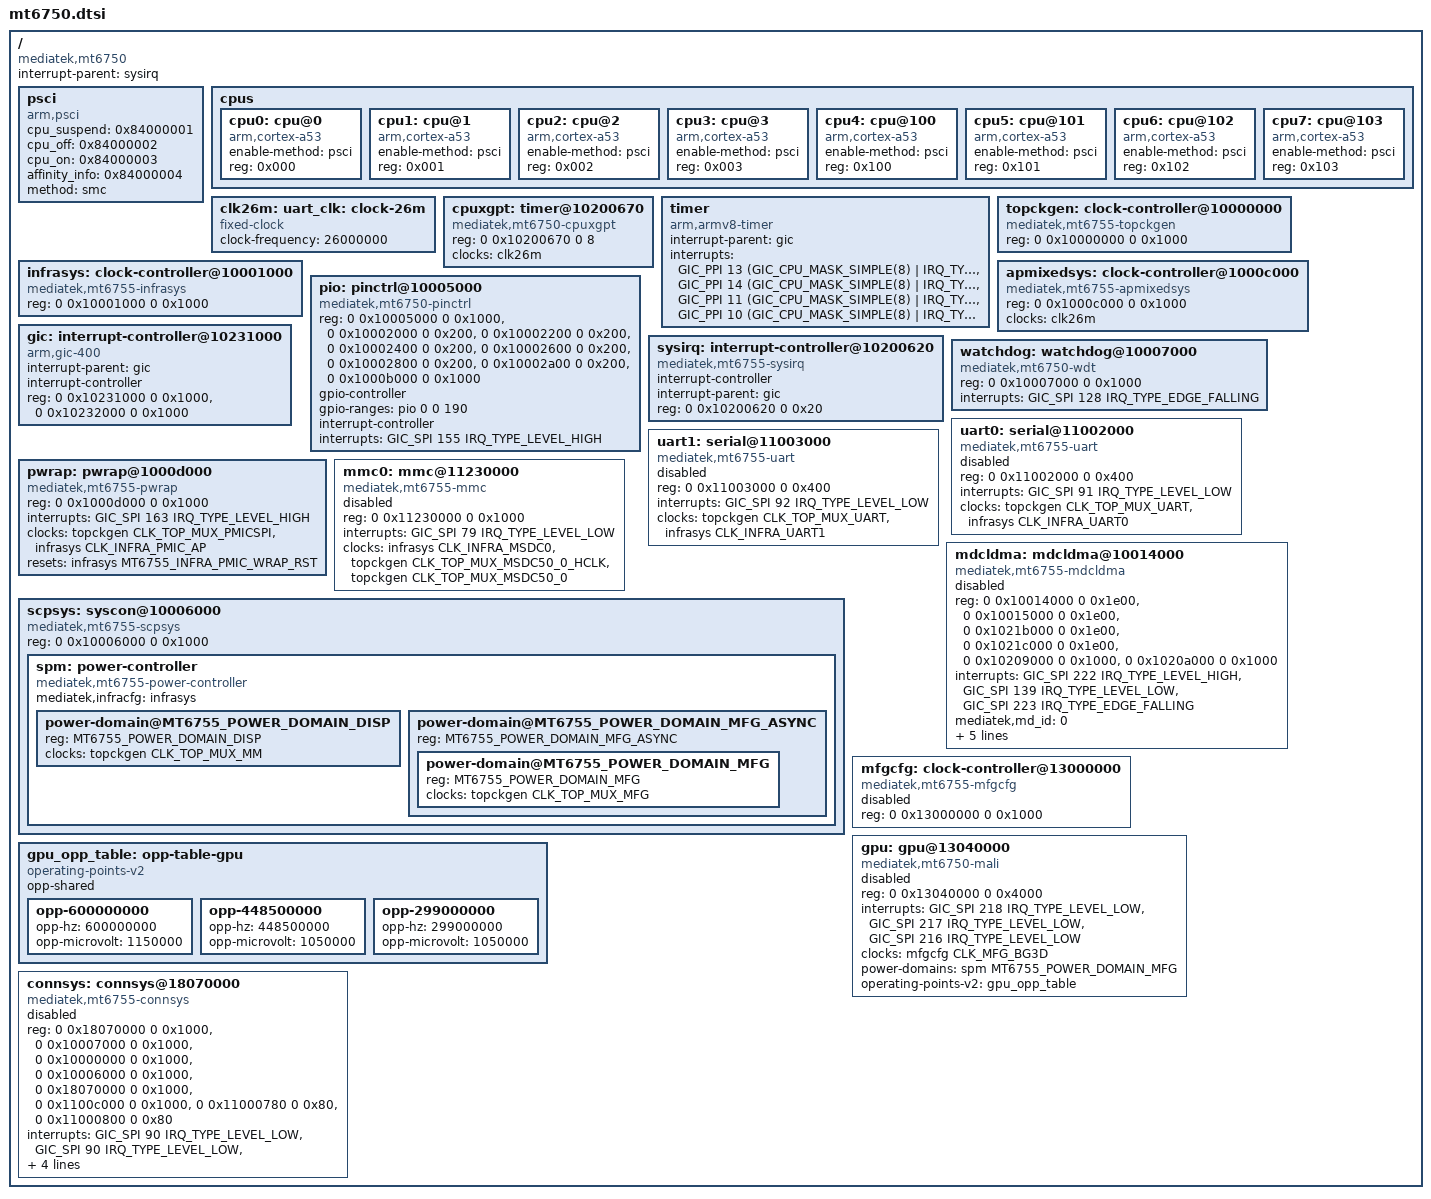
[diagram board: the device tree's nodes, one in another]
// SPDX-License-Identifier: GPL-2.0-only
/*
 * Copyright (c) 2016 MediaTek Inc.
 * Author: Mars.C <mars.cheng@mediatek.com>
 */

#include <dt-bindings/clock/mediatek,mt6755-clk.h>
#include <dt-bindings/interrupt-controller/irq.h>
#include <dt-bindings/interrupt-controller/arm-gic.h>
#include <dt-bindings/power/mediatek,mt6755-power.h>
#include <dt-bindings/reset/mt6755-resets.h>

/ {
	compatible = "mediatek,mt6750";
	interrupt-parent = <&sysirq>;
	#address-cells = <2>;
	#size-cells = <2>;

	psci {
		compatible = "arm,psci";
		cpu_suspend = <0x84000001>;
		cpu_off = <0x84000002>;
		cpu_on = <0x84000003>;
		affinity_info = <0x84000004>;
		method = "smc";
	};

	cpus {
		#address-cells = <1>;
		#size-cells = <0>;

		cpu0: cpu@0 {
			device_type = "cpu";
			compatible = "arm,cortex-a53";
			enable-method = "psci";
			reg = <0x000>;
		};

		cpu1: cpu@1 {
			device_type = "cpu";
			compatible = "arm,cortex-a53";
			enable-method = "psci";
			reg = <0x001>;
		};

		cpu2: cpu@2 {
			device_type = "cpu";
			compatible = "arm,cortex-a53";
			enable-method = "psci";
			reg = <0x002>;
		};

		cpu3: cpu@3 {
			device_type = "cpu";
			compatible = "arm,cortex-a53";
			enable-method = "psci";
			reg = <0x003>;
		};

		cpu4: cpu@100 {
			device_type = "cpu";
			compatible = "arm,cortex-a53";
			enable-method = "psci";
			reg = <0x100>;
		};

		cpu5: cpu@101 {
			device_type = "cpu";
			compatible = "arm,cortex-a53";
			enable-method = "psci";
			reg = <0x101>;
		};

		cpu6: cpu@102 {
			device_type = "cpu";
			compatible = "arm,cortex-a53";
			enable-method = "psci";
			reg = <0x102>;
		};

		cpu7: cpu@103 {
			device_type = "cpu";
			compatible = "arm,cortex-a53";
			enable-method = "psci";
			reg = <0x103>;
		};
	};

	clk26m: uart_clk: clock-26m {
		compatible = "fixed-clock";
		clock-frequency = <26000000>;
		#clock-cells = <0>;
	};

	cpuxgpt: timer@10200670 {
		compatible = "mediatek,mt6750-cpuxgpt";
		reg = <0 0x10200670 0 8>;
		clocks = <&clk26m>;
	};

	timer {
		compatible = "arm,armv8-timer";
		interrupt-parent = <&gic>;
		interrupts = <GIC_PPI 13
			     (GIC_CPU_MASK_SIMPLE(8) | IRQ_TYPE_LEVEL_LOW)>,
			     <GIC_PPI 14
			     (GIC_CPU_MASK_SIMPLE(8) | IRQ_TYPE_LEVEL_LOW)>,
			     <GIC_PPI 11
			     (GIC_CPU_MASK_SIMPLE(8) | IRQ_TYPE_LEVEL_LOW)>,
			     <GIC_PPI 10
			     (GIC_CPU_MASK_SIMPLE(8) | IRQ_TYPE_LEVEL_LOW)>;
	};

	topckgen: clock-controller@10000000 {
		compatible = "mediatek,mt6755-topckgen", "syscon";
		reg = <0 0x10000000 0 0x1000>;
		#clock-cells = <1>;
	};

	infrasys: clock-controller@10001000 {
		compatible = "mediatek,mt6755-infrasys", "syscon";
		reg = <0 0x10001000 0 0x1000>;
		#clock-cells = <1>;
		#reset-cells = <1>;
	};

	apmixedsys: clock-controller@1000c000 {
		compatible = "mediatek,mt6755-apmixedsys";
		reg = <0 0x1000c000 0 0x1000>;
		clocks = <&clk26m>;
		clock-names = "clk26m";
		#clock-cells = <1>;
	};

	pio: pinctrl@10005000 {
		compatible = "mediatek,mt6750-pinctrl";
		reg = <0 0x10005000 0 0x1000>,
		      <0 0x10002000 0 0x200>,
		      <0 0x10002200 0 0x200>,
		      <0 0x10002400 0 0x200>,
		      <0 0x10002600 0 0x200>,
		      <0 0x10002800 0 0x200>,
		      <0 0x10002a00 0 0x200>,
		      <0 0x1000b000 0 0x1000>;
		reg-names = "gpio", "iocfg0", "iocfg1", "iocfg2",
			    "iocfg3", "iocfg4", "iocfg5", "eint";
		gpio-controller;
		#gpio-cells = <2>;
		gpio-ranges = <&pio 0 0 190>;
		interrupt-controller;
		#address-cells = <0>;
		#interrupt-cells = <2>;
		interrupts = <GIC_SPI 155 IRQ_TYPE_LEVEL_HIGH>;
	};

	sysirq: interrupt-controller@10200620 {
		compatible = "mediatek,mt6755-sysirq",
			     "mediatek,mt6577-sysirq";
		interrupt-controller;
		#address-cells = <0>;
		#interrupt-cells = <3>;
		interrupt-parent = <&gic>;
		reg = <0 0x10200620 0 0x20>;
	};

	gic: interrupt-controller@10231000 {
		compatible = "arm,gic-400";
		#interrupt-cells = <3>;
		interrupt-parent = <&gic>;
		interrupt-controller;
		#address-cells = <0>;
		reg = <0 0x10231000 0 0x1000>,
		      <0 0x10232000 0 0x1000>;
	};

	watchdog: watchdog@10007000 {
		compatible = "mediatek,mt6750-wdt";
		reg = <0 0x10007000 0 0x1000>;
		interrupts = <GIC_SPI 128 IRQ_TYPE_EDGE_FALLING>;
	};

	uart0: serial@11002000 {
		compatible = "mediatek,mt6755-uart",
			     "mediatek,mt6577-uart";
		reg = <0 0x11002000 0 0x400>;
		interrupts = <GIC_SPI 91 IRQ_TYPE_LEVEL_LOW>;
		clocks = <&topckgen CLK_TOP_MUX_UART>,
			 <&infrasys CLK_INFRA_UART0>;
		clock-names = "baud", "bus";
		status = "disabled";
	};

	uart1: serial@11003000 {
		compatible = "mediatek,mt6755-uart",
			     "mediatek,mt6577-uart";
		reg = <0 0x11003000 0 0x400>;
		interrupts = <GIC_SPI 92 IRQ_TYPE_LEVEL_LOW>;
		clocks = <&topckgen CLK_TOP_MUX_UART>,
			 <&infrasys CLK_INFRA_UART1>;
		clock-names = "baud", "bus";
		status = "disabled";
	};

	/*
	 * PMIC wrapper and eMMC controller for the storage path.
	 *
	 * Values are copied from the stock MT6750 3.18 tree that Meizu's
	 * MT6750 boards are built from
	 * (android_kernel_collection_mt6750-P-ex2/kernel-3.18/arch/arm64/
	 * boot/dts/mt6755.dts: pwrap@1000d000 at :612-625, msdc0@11230000
	 * at :45-52) and match the mainline MT6755 dtsi. The MT6353 PMIC
	 * node is board specific and lives in the board DTS; it carries no
	 * interrupt because no MT6353 nIRQ EINT number is proven.
	 */
	pwrap: pwrap@1000d000 {
		compatible = "mediatek,mt6755-pwrap";
		reg = <0 0x1000d000 0 0x1000>;
		reg-names = "pwrap";
		interrupts = <GIC_SPI 163 IRQ_TYPE_LEVEL_HIGH>;
		clocks = <&topckgen CLK_TOP_MUX_PMICSPI>,
			 <&infrasys CLK_INFRA_PMIC_AP>;
		clock-names = "spi", "wrap";
		resets = <&infrasys MT6755_INFRA_PMIC_WRAP_RST>;
		reset-names = "pwrap";
	};

	/*
	 * MD1 cellular modem: CLDMA DMA rings plus the CCIF doorbell.
	 * MT6750 is an MT6755 derivative and shares its die, so the
	 * register windows and IRQs are the MT6755 ones (vendor
	 * mt6755.dtsi: CLDMA AO 0x10014000/0x10015000, CLDMA PD
	 * 0x1021b000/0x1021c000, CCIF 0x10209000/0x1020a000, IRQ 222
	 * (CLDMA), 139 (CCIF) and 223 (MD watchdog)).
	 */
	mdcldma: mdcldma@10014000 {
		compatible = "mediatek,mt6755-mdcldma";
		reg = <0 0x10014000 0 0x1e00>,	/* AP CLDMA AO */
		      <0 0x10015000 0 0x1e00>,	/* MD CLDMA AO */
		      <0 0x1021b000 0 0x1e00>,	/* AP CLDMA PD */
		      <0 0x1021c000 0 0x1e00>,	/* MD CLDMA PD */
		      <0 0x10209000 0 0x1000>,	/* AP CCIF */
		      <0 0x1020a000 0 0x1000>;	/* MD CCIF */
		interrupts = <GIC_SPI 222 IRQ_TYPE_LEVEL_HIGH>,
			     <GIC_SPI 139 IRQ_TYPE_LEVEL_LOW>,
			     <GIC_SPI 223 IRQ_TYPE_EDGE_FALLING>;
		mediatek,md_id = <0>;
		mediatek,cldma_capability = <6>;
		mediatek,md_smem_size = <0x100000>;
		clocks = <&infrasys CLK_INFRA_CCIF_AP>,
			 <&infrasys CLK_INFRA_CCIF_MD>,
			 <&infrasys CLK_INFRA_CLDMA_BCLK>;
		clock-names = "ccif-ap", "ccif-md", "cldma";
		status = "disabled";
	};

	mmc0: mmc@11230000 {
		compatible = "mediatek,mt6755-mmc", "mediatek,mt6795-mmc";
		reg = <0 0x11230000 0 0x1000>;
		interrupts = <GIC_SPI 79 IRQ_TYPE_LEVEL_LOW>;
		clocks = <&infrasys CLK_INFRA_MSDC0>,
			 <&topckgen CLK_TOP_MUX_MSDC50_0_HCLK>,
			 <&topckgen CLK_TOP_MUX_MSDC50_0>;
		clock-names = "source", "hclk", "source_cg";
		status = "disabled";
	};

	/*
	 * GPU support for MT6750 (the MT6755 silicon family: 8x Cortex-A53,
	 * Mali-T860MP2 at 0x13040000). The MT6750 boards include this file
	 * directly, so the GPU nodes are described here, identical to the
	 * MT6755 ones in mt6755.dtsi: JOB=SPI218 MMU=SPI217 GPU=SPI216 all
	 * LEVEL_LOW, core clock mfgcfg MFG_BG3D parented on the topckgen
	 * MFG mux, MTCMOS chain MFG_ASYNC -> MFG.
	 */
	scpsys: syscon@10006000 {
		compatible = "mediatek,mt6755-scpsys", "syscon", "simple-mfd";
		reg = <0 0x10006000 0 0x1000>;

		spm: power-controller {
			compatible = "mediatek,mt6755-power-controller";
			#address-cells = <1>;
			#size-cells = <0>;
			#power-domain-cells = <1>;
			mediatek,infracfg = <&infrasys>;

			power-domain@MT6755_POWER_DOMAIN_DISP {
				reg = <MT6755_POWER_DOMAIN_DISP>;
				#power-domain-cells = <0>;
				clocks = <&topckgen CLK_TOP_MUX_MM>;
				clock-names = "mm";
			};

			power-domain@MT6755_POWER_DOMAIN_MFG_ASYNC {
				reg = <MT6755_POWER_DOMAIN_MFG_ASYNC>;
				#address-cells = <1>;
				#size-cells = <0>;
				#power-domain-cells = <0>;

				power-domain@MT6755_POWER_DOMAIN_MFG {
					reg = <MT6755_POWER_DOMAIN_MFG>;
					#power-domain-cells = <0>;
					clocks = <&topckgen CLK_TOP_MUX_MFG>;
					clock-names = "mfg";
				};
			};
		};
	};

	/*
	 * mfgcfg gate: registers inertly, MFG_ASYNC is powered by the GPU
	 * consumer (panfrost) before BG3D is enabled. See
	 * drivers/clk/mediatek/clk-mt6755-mfg.c.
	 */
	mfgcfg: clock-controller@13000000 {
		compatible = "mediatek,mt6755-mfgcfg";
		reg = <0 0x13000000 0 0x1000>;
		#clock-cells = <1>;
		status = "disabled";
	};

	gpu: gpu@13040000 {
		compatible = "mediatek,mt6750-mali", "arm,mali-t860",
			     "arm,mali-midgard";
		reg = <0 0x13040000 0 0x4000>;
		interrupts = <GIC_SPI 218 IRQ_TYPE_LEVEL_LOW>,
			     <GIC_SPI 217 IRQ_TYPE_LEVEL_LOW>,
			     <GIC_SPI 216 IRQ_TYPE_LEVEL_LOW>;
		interrupt-names = "job", "mmu", "gpu";
		clocks = <&mfgcfg CLK_MFG_BG3D>;
		clock-names = "core";
		power-domains = <&spm MT6755_POWER_DOMAIN_MFG>;
		operating-points-v2 = <&gpu_opp_table>;
		status = "disabled";
	};

	/*
	 * MT6750 GPU DVFS table, same profile as MT6755 (stock
	 * mt_gpufreq.c "HPM": 600 / 448.5 / 299 MHz).
	 */
	gpu_opp_table: opp-table-gpu {
		compatible = "operating-points-v2";
		opp-shared;

		opp-600000000 {
			opp-hz = /bits/ 64 <600000000>;
			opp-microvolt = <1150000>;
		};

		opp-448500000 {
			opp-hz = /bits/ 64 <448500000>;
			opp-microvolt = <1050000>;
		};

		opp-299000000 {
			opp-hz = /bits/ 64 <299000000>;
			opp-microvolt = <1050000>;
		};
	};
		/*
		 * CONSYS (MT6750 variant of the MT6755 combo subsystem):
		 * CONN MCU block, AP reset generator, topckgen, SPM, CONN AXI
		 * protection and the BTIF UART with its APDMA pair.
		 */
		connsys: connsys@18070000 {
			compatible = "mediatek,mt6755-connsys";
			reg = <0 0x18070000 0 0x1000>,
			      <0 0x10007000 0 0x1000>,
			      <0 0x10000000 0 0x1000>,
			      <0 0x10006000 0 0x1000>,
			      <0 0x18070000 0 0x1000>,
			      <0 0x1100c000 0 0x1000>,
			      <0 0x11000780 0 0x80>,
			      <0 0x11000800 0 0x80>;
			reg-names = "mcu", "ap_rgu", "topckgen", "spm", "axi",
				    "btif", "btif_tx_dma", "btif_rx_dma";
			interrupts = <GIC_SPI 90 IRQ_TYPE_LEVEL_LOW>,
				     <GIC_SPI 90 IRQ_TYPE_LEVEL_LOW>,
				     <GIC_SPI 111 IRQ_TYPE_LEVEL_LOW>,
				     <GIC_SPI 112 IRQ_TYPE_LEVEL_LOW>;
			interrupt-names = "btif", "btif_tx_dma", "btif_rx_dma";
			clocks = <&infrasys CLK_INFRA_BTIF>;
			clock-names = "btif";
			mediatek,connsys-chip-id = <0x6750>;
			status = "disabled";
		};

};
